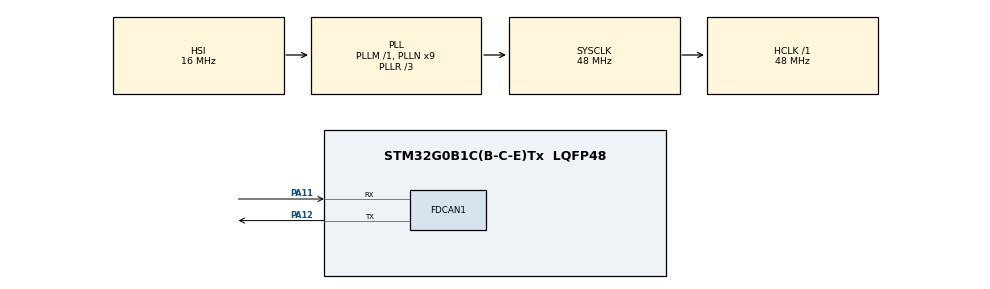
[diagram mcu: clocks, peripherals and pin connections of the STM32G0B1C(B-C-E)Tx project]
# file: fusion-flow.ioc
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FDCAN1.AutoRetransmission=ENABLE
FDCAN1.CalculateBaudRateNominal=500000
FDCAN1.CalculateTimeBitNominal=2000
FDCAN1.CalculateTimeQuantumNominal=20.833333333333332
FDCAN1.DataTimeSeg1=13
FDCAN1.DataTimeSeg2=10
FDCAN1.FrameFormat=FDCAN_FRAME_FD_BRS
FDCAN1.NominalPrescaler=1
FDCAN1.NominalSyncJumpWidth=19
FDCAN1.NominalTimeSeg1=76
FDCAN1.NominalTimeSeg2=19
FDCAN1.ProtocolException=ENABLE
FDCAN1.StdFiltersNbr=1
Mcu.Family=STM32G0
Mcu.Name=STM32G0B1C(B-C-E)Tx
Mcu.Package=LQFP48
NVIC.TIM16_FDCAN_IT0_IRQn=true\:0\:0\:false\:false\:true\:true\:true\:true
PA11\ [PA9].GPIO_Speed=GPIO_SPEED_FREQ_VERY_HIGH
PA11\ [PA9].Mode=FDCAN_Activate
PA11\ [PA9].Signal=FDCAN1_RX
PA12\ [PA10].GPIO_Mode=GPIO_MODE_AF_PP
PA12\ [PA10].GPIO_Speed=GPIO_SPEED_FREQ_VERY_HIGH
PA12\ [PA10].Mode=FDCAN_Activate
PA12\ [PA10].Signal=FDCAN1_TX
ProjectManager.HeapSize=0x200
ProjectManager.StackSize=0x400
ProjectManager.TargetToolchain=STM32CubeIDE
RCC.ADCFreq_Value=48000000
RCC.AHBFreq_Value=48000000
RCC.CortexFreq_Value=48000000
RCC.EXTERNAL_CLOCK_VALUE=48000
RCC.HCLKFreq_Value=48000000
RCC.HSE_VALUE=8000000
RCC.HSI48_VALUE=48000000
RCC.HSI_VALUE=16000000
RCC.LSE_VALUE=32768
RCC.PLLN=9
RCC.PLLR=RCC_PLLR_DIV3
RCC.SYSCLKFreq_VALUE=48000000
RCC.SYSCLKSource=RCC_SYSCLKSOURCE_PLLCLK
RCC.USBFreq_Value=48000000
RCC.VCOOutputFreq_Value=144000000
VP_SYS_VS_DBSignals.Mode=DisableDeadBatterySignals
board=custom

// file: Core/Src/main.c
/* USER CODE BEGIN Header */
/**
  ******************************************************************************
  * @file           : main.c
  * @brief          : Main program body
  ******************************************************************************
  * @attention
  *
  * Copyright (c) 2026 STMicroelectronics.
  * All rights reserved.
  *
  * This software is licensed under terms that can be found in the LICENSE file
  * in the root directory of this software component.
  * If no LICENSE file comes with this software, it is provided AS-IS.
  *
  ******************************************************************************
  */
/* USER CODE END Header */
#include "main.h"
#include "fdcan.h"
#include "gpio.h"

/* USER CODE BEGIN Includes */
#include "inc.hpp"
/* USER CODE END Includes */

void SystemClock_Config(void);

int main(void)
{

  /* MCU Configuration--------------------------------------------------------*/

  /* Reset of all peripherals, Initializes the Flash interface and the Systick. */
  HAL_Init();

  /* Configure the system clock */
  SystemClock_Config();

  /* Initialize all configured peripherals */
  MX_GPIO_Init();
  MX_FDCAN1_Init();
  /* USER CODE BEGIN 2 */
  main_app();
  /* USER CODE END 2 */

  /* Infinite loop */
  while (1)
  {

  }
}

void SystemClock_Config(void)
{
  RCC_OscInitTypeDef RCC_OscInitStruct = {0};
  RCC_ClkInitTypeDef RCC_ClkInitStruct = {0};

  /** Configure the main internal regulator output voltage
  */
  HAL_PWREx_ControlVoltageScaling(PWR_REGULATOR_VOLTAGE_SCALE1);

  /** Initializes the RCC Oscillators according to the specified parameters
  * in the RCC_OscInitTypeDef structure.
  */
  RCC_OscInitStruct.OscillatorType = RCC_OSCILLATORTYPE_HSI;
  RCC_OscInitStruct.HSIState = RCC_HSI_ON;
  RCC_OscInitStruct.HSIDiv = RCC_HSI_DIV1;
  RCC_OscInitStruct.HSICalibrationValue = RCC_HSICALIBRATION_DEFAULT;
  RCC_OscInitStruct.PLL.PLLState = RCC_PLL_ON;
  RCC_OscInitStruct.PLL.PLLSource = RCC_PLLSOURCE_HSI;
  RCC_OscInitStruct.PLL.PLLM = RCC_PLLM_DIV1;
  RCC_OscInitStruct.PLL.PLLN = 9;
  RCC_OscInitStruct.PLL.PLLP = RCC_PLLP_DIV2;
  RCC_OscInitStruct.PLL.PLLQ = RCC_PLLQ_DIV2;
  RCC_OscInitStruct.PLL.PLLR = RCC_PLLR_DIV3;
  if (HAL_RCC_OscConfig(&RCC_OscInitStruct) != HAL_OK)
  {
    Error_Handler();
  }

  /** Initializes the CPU, AHB and APB buses clocks
  */
  RCC_ClkInitStruct.ClockType = RCC_CLOCKTYPE_HCLK|RCC_CLOCKTYPE_SYSCLK
                              |RCC_CLOCKTYPE_PCLK1;
  RCC_ClkInitStruct.SYSCLKSource = RCC_SYSCLKSOURCE_PLLCLK;
  RCC_ClkInitStruct.AHBCLKDivider = RCC_SYSCLK_DIV1;
  RCC_ClkInitStruct.APB1CLKDivider = RCC_HCLK_DIV1;

  if (HAL_RCC_ClockConfig(&RCC_ClkInitStruct, FLASH_LATENCY_1) != HAL_OK)
  {
    Error_Handler();
  }
}

void Error_Handler(void)
{
  __disable_irq();
  while (1)
  {
  }
}
